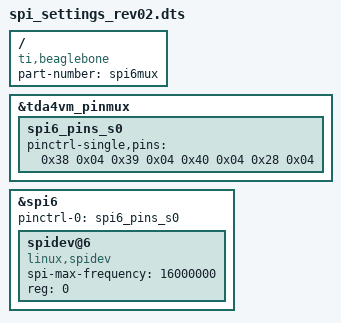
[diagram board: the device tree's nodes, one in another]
/* Enabling SPIDEV with cape manager : URL reference */
/* https://elinux.org/BeagleBone_Black_Enable_SPIDEV */

/* SPI6 */
/* D1 Output and D0 Input */
/* INPUT_PULLUP : 0x30, OUTPUT_PULLUP : 0x10 */

/dts-v1/;
/plugin/;

/ {
    compatible = "ti,beaglebone", "ti,beaglebone-ai-64";

    /* identification */
    part-number = "spi6mux";

    fragment@0 {
        target = <&tda4vm_pinmux>;
        __overlay__ {
            spi6_pins_s0: spi6_pins_s0 {
                        pinctrl-single,pins = <
                                0x38 0x04      /* spi6_sclk.spi6_sclk | MODE4 */
                                0x39 0x04      /* spi6_d0.spi6_d0 | MODE4 */
                                0x40 0x04      /* spi6_d1.spi6_d1 | MODE4 */
                                0x28 0x04      /* spi6_cs0.spi6_cs0 | MODE4 */
                >;
            };
        };
    };

    fragment@1 {
        target = <&spi6>;
        __overlay__ {

             #address-cells = <1>;
             #size-cells = <0>;
             status = "okay";
             pinctrl-names = "default";
             pinctrl-0 = <&spi6_pins_s0>;

             spidev@6 {
                 spi-max-frequency = <16000000>;
                 reg = <0>;
                 compatible = "linux,spidev";
            };
        };
    };
};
